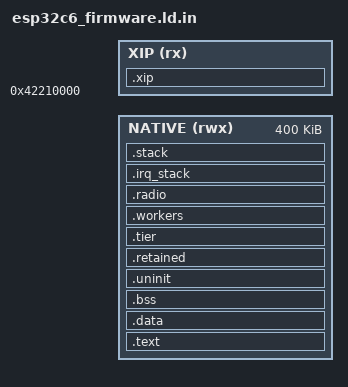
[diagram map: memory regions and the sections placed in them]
/*
 * Tiku Operating System v0.06
 * Simple. Persistent. Intelligent.
 * http://tiku-os.org
 *
 * Authors: Ambuj Varshney <ambuj@tiku-os.org>
 *
 * esp32c6_firmware.ld.in - Native SRAM ownership and application budgets.
 *
 * SPDX-License-Identifier: Apache-2.0
 */
OUTPUT_ARCH(riscv)
ENTRY(c6_cold_entry)
MEMORY { NATIVE (rwx) : ORIGIN = @BASE@, LENGTH = 400K
 XIP (rx) : ORIGIN = 0x42210000, LENGTH = @XIP_BYTES@ }
SECTIONS {
    .xip : {
        __c6_xip_start = .;
        @RADIO_XIP@
        *tiku_shell*.o(.text .text.* .rodata .rodata.* .srodata .srodata.*)
        *tiku_basic.o(.text .text.* .rodata .rodata.* .srodata .srodata.*)
        . = ALIGN(4);
        __c6_xip_end = .;
    } > XIP

    .text : {
        __native_image_start = .;
        KEEP(*(.text.entry))
        . = ALIGN(256);
        KEEP(*(.text.vectors))
        *(.iram1 .iram1.*)
        *(EXCLUDE_FILE (*tiku_basic.o) .text .text.*)
        *(EXCLUDE_FILE (*tiku_basic.o) .rodata .rodata.* .srodata .srodata.*)
        . = ALIGN(4);
    } > NATIVE
    .data : {
        __global_pointer$ = . + 0x800;
        *(.data .data.* .sdata .sdata.*)
        *(.dram1 .dram1.*)
        . = ALIGN(4);
        __tiku_cells_start = .;
        KEEP(*(.tiku_cells))
        __tiku_cells_end = .;
        __native_image_end = .;
    } > NATIVE
    .bss (NOLOAD) : {
        __bss_start = .;
        *(.bss .bss.* .sbss .sbss.* COMMON)
        . = ALIGN(16);
        __bss_end = .;
    } > NATIVE
    .uninit (NOLOAD) : ALIGN(16) {
        __uninit_start = .;
        KEEP(*(.persistent.layout))
        ASSERT(. <= __uninit_start+1024, "C6 layout control exceeds fixed prefix");
        . = __uninit_start+(@STORAGE@ ? 1024 : 0);
        __c6_recovery_start = .;
        KEEP(*(.persistent.arch))
        __c6_recovery_end = .;
        ASSERT(__c6_recovery_end-__c6_recovery_start == (@STORAGE@ ? 4112 : 0), "C6 recovery control size changed");
        *(.persistent .persistent.* .uninit .uninit.*)
        . = ALIGN(16);
        __uninit_end = .;
    } > NATIVE
    ASSERT(@STORAGE@ || SIZEOF(.uninit)==0, "C6 durable placement requires storage")
    .retained (NOLOAD) : ALIGN(16) {
        __retained_start = .;
        *(.retained .retained.*)
        . = ALIGN(16);
        __retained_end = .;
    } > NATIVE
    ASSERT(__uninit_end-__uninit_start <= 8176, "C6 durable mirror capacity exceeded")
    ASSERT(__retained_end-__retained_start <= (@SHELL@ ? 8192 : 4096), "C6 retained budget exceeded")
    .tier (NOLOAD) : ALIGN(64) {
        __tier_sram_start = .;
        . = ORIGIN(NATIVE)+LENGTH(NATIVE)-4096-32768-65536-2048-64-8192;
        __tier_sram_end = .;
    } > NATIVE
    .workers (NOLOAD) : {
        __worker_reserve_start = .;
        *(.c6.worker_stacks)
        __worker_stacks_end = .;
        . = __worker_reserve_start+32768;
        __worker_reserve_end = .;
    } > NATIVE
    .radio (NOLOAD) : {
        __radio_reserve_start = .; . += 65536; __radio_reserve_end = .;
    } > NATIVE
    .irq_stack (NOLOAD) : {
        __native_irq_bottom = .; . += 2048; __native_irq_top = .;
    } > NATIVE
    .stack (NOLOAD) : {
        native_stack_guard = .; . += 64;
        __native_stack_bottom = .; . += 8192; __native_stack_top = .;
    } > NATIVE
    __native_arena_end = ORIGIN(NATIVE)+LENGTH(NATIVE);
    __c6_layout_version = 2;
    __c6_shell_profile = @SHELL@;
    __datastart = ADDR(.data);
    _end = __retained_end;
    _etext = __native_image_end;
    __stack = __native_stack_top;
    __sram_start = ORIGIN(NATIVE);
    __sram_end = ORIGIN(NATIVE)+LENGTH(NATIVE);
    __tiku_stack_bottom = __native_stack_bottom;
    __tiku_stack_guard_start = native_stack_guard;
    __c6_board_id = 0x50344336;
    __c6_firmware_build = @BUILD@;
    __c6_tier_floor = @TIER_FLOOR@;
    ASSERT(__tier_sram_end-__tier_sram_start >= __c6_tier_floor, "C6 SRAM tier below declared floor")
    ASSERT(__worker_stacks_end-__worker_reserve_start <= 32768, "C6 worker stacks exceed reservation")
    ASSERT(__native_stack_top == 0x4086d000, "C6 cold-entry stack overlap")
    ASSERT(__native_image_end-__native_image_start <= 131072, "C6 initialized image exceeds budget")
    ASSERT(__native_arena_end <= 0x4086e000, "C6 bootloader SRAM overlap")
    /DISCARD/ : { *(.comment .note .note.* .eh_frame .eh_frame.*) }
}
